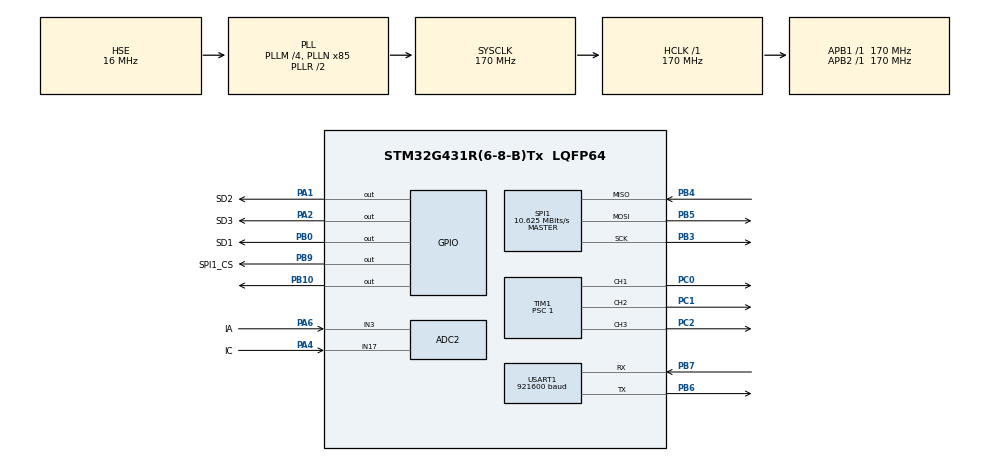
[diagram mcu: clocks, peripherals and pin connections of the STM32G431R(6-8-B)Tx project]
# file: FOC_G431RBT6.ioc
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ADC2.ContinuousConvMode=DISABLE
ADC2.EOCSelection=ADC_EOC_SINGLE_CONV
ADC2.EnableInjectedConversion=ENABLE
ADC2.EnableRegularConversion=DISABLE
ADC2.ExternalTrigInjecConv=ADC_EXTERNALTRIGINJEC_T1_TRGO
ADC2.InjNumberOfConversion=2
ADC2.InjectedChannel-1\#ChannelInjectedConversion=ADC_CHANNEL_3
ADC2.InjectedChannel-3\#ChannelInjectedConversion=ADC_CHANNEL_17
ADC2.InjectedOffsetNumber-1\#ChannelInjectedConversion=ADC_OFFSET_NONE
ADC2.InjectedOffsetNumber-3\#ChannelInjectedConversion=ADC_OFFSET_NONE
ADC2.InjectedRank-1\#ChannelInjectedConversion=1
ADC2.InjectedRank-3\#ChannelInjectedConversion=2
ADC2.InjectedSamplingTime-1\#ChannelInjectedConversion=ADC_SAMPLETIME_24CYCLES_5
ADC2.InjectedSamplingTime-3\#ChannelInjectedConversion=ADC_SAMPLETIME_24CYCLES_5
ADC2.injectedQueueMode=DISABLE
Dma.Request0=USART1_RX
Dma.Request1=USART1_TX
Dma.Request2=SPI1_RX
Dma.Request3=SPI1_TX
Dma.SPI1_RX.2.Direction=DMA_PERIPH_TO_MEMORY
Dma.SPI1_RX.2.EventEnable=DISABLE
Dma.SPI1_RX.2.Instance=DMA1_Channel3
Dma.SPI1_RX.2.MemDataAlignment=DMA_MDATAALIGN_BYTE
Dma.SPI1_RX.2.MemInc=DMA_MINC_ENABLE
Dma.SPI1_RX.2.Mode=DMA_NORMAL
Dma.SPI1_RX.2.PeriphDataAlignment=DMA_PDATAALIGN_BYTE
Dma.SPI1_RX.2.PeriphInc=DMA_PINC_DISABLE
Dma.SPI1_RX.2.Polarity=HAL_DMAMUX_REQ_GEN_RISING
Dma.SPI1_RX.2.Priority=DMA_PRIORITY_LOW
Dma.SPI1_RX.2.RequestNumber=1
Dma.SPI1_RX.2.SignalID=NONE
Dma.SPI1_RX.2.SyncEnable=DISABLE
Dma.SPI1_RX.2.SyncPolarity=HAL_DMAMUX_SYNC_NO_EVENT
Dma.SPI1_RX.2.SyncRequestNumber=1
Dma.SPI1_RX.2.SyncSignalID=NONE
Dma.SPI1_TX.3.Direction=DMA_MEMORY_TO_PERIPH
Dma.SPI1_TX.3.EventEnable=DISABLE
Dma.SPI1_TX.3.Instance=DMA1_Channel4
Dma.SPI1_TX.3.MemDataAlignment=DMA_MDATAALIGN_BYTE
Dma.SPI1_TX.3.MemInc=DMA_MINC_ENABLE
Dma.SPI1_TX.3.Mode=DMA_NORMAL
Dma.SPI1_TX.3.PeriphDataAlignment=DMA_PDATAALIGN_BYTE
Dma.SPI1_TX.3.PeriphInc=DMA_PINC_DISABLE
Dma.SPI1_TX.3.Polarity=HAL_DMAMUX_REQ_GEN_RISING
Dma.SPI1_TX.3.Priority=DMA_PRIORITY_LOW
Dma.SPI1_TX.3.RequestNumber=1
Dma.SPI1_TX.3.SignalID=NONE
Dma.SPI1_TX.3.SyncEnable=DISABLE
Dma.SPI1_TX.3.SyncPolarity=HAL_DMAMUX_SYNC_NO_EVENT
Dma.SPI1_TX.3.SyncRequestNumber=1
Dma.SPI1_TX.3.SyncSignalID=NONE
Dma.USART1_RX.0.Direction=DMA_PERIPH_TO_MEMORY
Dma.USART1_RX.0.EventEnable=DISABLE
Dma.USART1_RX.0.Instance=DMA1_Channel1
Dma.USART1_RX.0.MemDataAlignment=DMA_MDATAALIGN_BYTE
Dma.USART1_RX.0.MemInc=DMA_MINC_ENABLE
Dma.USART1_RX.0.Mode=DMA_NORMAL
Dma.USART1_RX.0.PeriphDataAlignment=DMA_PDATAALIGN_BYTE
Dma.USART1_RX.0.PeriphInc=DMA_PINC_DISABLE
Dma.USART1_RX.0.Polarity=HAL_DMAMUX_REQ_GEN_RISING
Dma.USART1_RX.0.Priority=DMA_PRIORITY_LOW
Dma.USART1_RX.0.RequestNumber=1
Dma.USART1_RX.0.SignalID=NONE
Dma.USART1_RX.0.SyncEnable=DISABLE
Dma.USART1_RX.0.SyncPolarity=HAL_DMAMUX_SYNC_NO_EVENT
Dma.USART1_RX.0.SyncRequestNumber=1
Dma.USART1_RX.0.SyncSignalID=NONE
Dma.USART1_TX.1.Direction=DMA_MEMORY_TO_PERIPH
Dma.USART1_TX.1.EventEnable=DISABLE
Dma.USART1_TX.1.Instance=DMA1_Channel2
Dma.USART1_TX.1.MemDataAlignment=DMA_MDATAALIGN_BYTE
Dma.USART1_TX.1.MemInc=DMA_MINC_ENABLE
Dma.USART1_TX.1.Mode=DMA_NORMAL
Dma.USART1_TX.1.PeriphDataAlignment=DMA_PDATAALIGN_BYTE
Dma.USART1_TX.1.PeriphInc=DMA_PINC_DISABLE
Dma.USART1_TX.1.Polarity=HAL_DMAMUX_REQ_GEN_RISING
Dma.USART1_TX.1.Priority=DMA_PRIORITY_MEDIUM
Dma.USART1_TX.1.RequestNumber=1
Dma.USART1_TX.1.SignalID=NONE
Dma.USART1_TX.1.SyncEnable=DISABLE
Dma.USART1_TX.1.SyncPolarity=HAL_DMAMUX_SYNC_NO_EVENT
Dma.USART1_TX.1.SyncRequestNumber=1
Dma.USART1_TX.1.SyncSignalID=NONE
Mcu.Family=STM32G4
Mcu.Name=STM32G431R(6-8-B)Tx
Mcu.Package=LQFP64
Mcu.UserConstants=motor_pwm_freq,24000
NVIC.ADC1_2_IRQn=true\:0\:0\:true\:false\:true\:true\:true\:true
NVIC.DMA1_Channel1_IRQn=true\:0\:0\:false\:false\:true\:false\:true\:true
NVIC.DMA1_Channel2_IRQn=true\:0\:0\:false\:false\:true\:false\:true\:true
NVIC.DMA1_Channel3_IRQn=true\:0\:0\:false\:false\:true\:false\:true\:true
NVIC.DMA1_Channel4_IRQn=true\:0\:0\:false\:false\:true\:false\:true\:true
NVIC.PriorityGroup=NVIC_PRIORITYGROUP_4
PA1.GPIO_Label=SD2
PA1.GPIO_Speed=GPIO_SPEED_FREQ_VERY_HIGH
PA1.PinState=GPIO_PIN_RESET
PA1.Signal=GPIO_Output
PA13.Mode=Serial_Wire
PA13.Signal=SYS_JTMS-SWDIO
PA14.Mode=Serial_Wire
PA14.Signal=SYS_JTCK-SWCLK
PA2.GPIO_Label=SD3
PA2.GPIO_Speed=GPIO_SPEED_FREQ_VERY_HIGH
PA2.PinState=GPIO_PIN_RESET
PA2.Signal=GPIO_Output
PA4.GPIO_Label=IC
PA4.Mode=IN17-Single-Ended
PA4.Signal=ADC2_IN17
PA6.GPIO_Label=IA
PA6.Mode=IN3-Single-Ended
PA6.Signal=ADC2_IN3
PB0.GPIO_Label=SD1
PB0.GPIO_Speed=GPIO_SPEED_FREQ_VERY_HIGH
PB0.PinState=GPIO_PIN_RESET
PB0.Signal=GPIO_Output
PB10.GPIO_Speed=GPIO_SPEED_FREQ_HIGH
PB10.PinState=GPIO_PIN_RESET
PB10.Signal=GPIO_Output
PB3.Mode=Full_Duplex_Master
PB3.Signal=SPI1_SCK
PB4.Mode=Full_Duplex_Master
PB4.Signal=SPI1_MISO
PB5.Mode=Full_Duplex_Master
PB5.Signal=SPI1_MOSI
PB6.Mode=Asynchronous
PB6.Signal=USART1_TX
PB7.Mode=Asynchronous
PB7.Signal=USART1_RX
PB9.GPIO_Label=SPI1_CS
PB9.PinState=GPIO_PIN_SET
PB9.Signal=GPIO_Output
PC0.Signal=S_TIM1_CH1
PC1.Signal=S_TIM1_CH2
PC2.Signal=S_TIM1_CH3
PF0-OSC_IN.Mode=HSE-External-Oscillator
PF0-OSC_IN.Signal=RCC_OSC_IN
PF1-OSC_OUT.Mode=HSE-External-Oscillator
PF1-OSC_OUT.Signal=RCC_OSC_OUT
ProjectManager.HeapSize=0x400
ProjectManager.StackSize=0x600
ProjectManager.TargetToolchain=MDK-ARM V5
RCC.ADC12Freq_Value=170000000
RCC.AHBFreq_Value=170000000
RCC.APB1Freq_Value=170000000
RCC.APB1TimFreq_Value=170000000
RCC.APB2Freq_Value=170000000
RCC.APB2TimFreq_Value=170000000
RCC.CortexFreq_Value=170000000
RCC.EXTERNAL_CLOCK_VALUE=12288000
RCC.HCLKFreq_Value=170000000
RCC.HSE_VALUE=16000000
RCC.HSI48_VALUE=48000000
RCC.HSI_VALUE=16000000
RCC.LSE_VALUE=32768
RCC.PLLM=RCC_PLLM_DIV4
RCC.PLLN=85
RCC.PLLSourceVirtual=RCC_PLLSOURCE_HSE
RCC.SYSCLKFreq_VALUE=170000000
RCC.SYSCLKSource=RCC_SYSCLKSOURCE_PLLCLK
RCC.USBFreq_Value=170000000
RCC.VCOOutputFreq_Value=340000000
SH.S_TIM1_CH1.0=TIM1_CH1,PWM Generation1 CH1
SH.S_TIM1_CH2.0=TIM1_CH2,PWM Generation2 CH2
SH.S_TIM1_CH3.0=TIM1_CH3,PWM Generation3 CH3
SPI1.BaudRatePrescaler=SPI_BAUDRATEPRESCALER_16
SPI1.CLKPhase=SPI_PHASE_2EDGE
SPI1.CLKPolarity=SPI_POLARITY_HIGH
SPI1.CalculateBaudRate=10.625 MBits/s
SPI1.DataSize=SPI_DATASIZE_8BIT
SPI1.Direction=SPI_DIRECTION_2LINES
SPI1.Mode=SPI_MODE_MASTER
SPI1.VirtualType=VM_MASTER
STMicroelectronics.X-CUBE-ALGOBUILD.1.4.0.LibraryCcDSPOoLibraryJjDSPOoLibrary=true
TIM1.AutoReloadPreload=TIM_AUTORELOAD_PRELOAD_ENABLE
TIM1.AutomaticOutput=TIM_AUTOMATICOUTPUT_DISABLE
TIM1.Break2Polarity=TIM_BREAK2POLARITY_LOW
TIM1.Break2State=TIM_BREAK2_DISABLE
TIM1.BreakPolarity=TIM_BREAKPOLARITY_LOW
TIM1.BreakState=TIM_BREAK_DISABLE
TIM1.Channel-PWM\ Generation1\ CH1=TIM_CHANNEL_1
TIM1.Channel-PWM\ Generation2\ CH2=TIM_CHANNEL_2
TIM1.Channel-PWM\ Generation3\ CH3=TIM_CHANNEL_3
TIM1.CounterMode=TIM_COUNTERMODE_CENTERALIGNED3
TIM1.LockLevel=TIM_LOCKLEVEL_1
TIM1.OCMode_PWM-PWM\ Generation1\ CH1=TIM_OCMODE_PWM2
TIM1.OCMode_PWM-PWM\ Generation2\ CH2=TIM_OCMODE_PWM2
TIM1.OCMode_PWM-PWM\ Generation3\ CH3=TIM_OCMODE_PWM2
TIM1.PeriodNoDither=(85000000/motor_pwm_freq)
TIM1.Prescaler=1
TIM1.RepetitionCounter=1
TIM1.TIM_MasterOutputTrigger=TIM_TRGO_UPDATE
USART1.BaudRate=921600
USART1.VirtualMode-Asynchronous=VM_ASYNC
VP_STMicroelectronics.X-CUBE-ALGOBUILD_VS_DSPOoLibraryJjLibrary_1.4.0_1.4.0.Mode=DSPOoLibraryJjLibrary
VP_SYS_VS_DBSignals.Mode=DisableDeadBatterySignals
VP_TIM1_VS_ClockSourceINT.Mode=Internal
board=custom

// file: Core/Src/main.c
/* USER CODE BEGIN Header */
/**
  ******************************************************************************
  * @file           : main.c
  * @brief          : Main program body
  ******************************************************************************
  * @attention
  *
  * Copyright (c) 2025 STMicroelectronics.
  * All rights reserved.
  *
  * This software is licensed under terms that can be found in the LICENSE file
  * in the root directory of this software component.
  * If no LICENSE file comes with this software, it is provided AS-IS.
  *
  ******************************************************************************
  */
/* USER CODE END Header */
#include "main.h"
#include "adc.h"
#include "dma.h"
#include "spi.h"
#include "tim.h"
#include "usart.h"
#include "gpio.h"

/* USER CODE BEGIN Includes */
#include <math.h>
/* USER CODE END Includes */

void SystemClock_Config(void);

int main(void)
{

  /* MCU Configuration--------------------------------------------------------*/

  /* Reset of all peripherals, Initializes the Flash interface and the Systick. */
  HAL_Init();

  /* Configure the system clock */
  SystemClock_Config();

  /* Initialize all configured peripherals */
  MX_GPIO_Init();
  MX_DMA_Init();
  MX_SPI1_Init();
  MX_USART1_UART_Init();
  MX_TIM1_Init();
  MX_ADC2_Init();
  /* USER CODE BEGIN 2 */
  uint8_t i=0;
  float temp;
  /* USER CODE END 2 */

  /* Infinite loop */
  while (1)
  {
//	HAL_UART_Transmit_DMA(&huart1, buf, sizeof(buf));
//	while (huart1.gState != HAL_UART_STATE_READY);
	temp=sinf(i*3.1415926/180);
	i++;
	HAL_UART_Transmit(&huart1, (uint8_t *)&i, sizeof(i), HAL_MAX_DELAY);
	HAL_Delay(1);
  }
}

void SystemClock_Config(void)
{
  RCC_OscInitTypeDef RCC_OscInitStruct = {0};
  RCC_ClkInitTypeDef RCC_ClkInitStruct = {0};

  /** Configure the main internal regulator output voltage
  */
  HAL_PWREx_ControlVoltageScaling(PWR_REGULATOR_VOLTAGE_SCALE1_BOOST);

  /** Initializes the RCC Oscillators according to the specified parameters
  * in the RCC_OscInitTypeDef structure.
  */
  RCC_OscInitStruct.OscillatorType = RCC_OSCILLATORTYPE_HSE;
  RCC_OscInitStruct.HSEState = RCC_HSE_ON;
  RCC_OscInitStruct.PLL.PLLState = RCC_PLL_ON;
  RCC_OscInitStruct.PLL.PLLSource = RCC_PLLSOURCE_HSE;
  RCC_OscInitStruct.PLL.PLLM = RCC_PLLM_DIV4;
  RCC_OscInitStruct.PLL.PLLN = 85;
  RCC_OscInitStruct.PLL.PLLP = RCC_PLLP_DIV2;
  RCC_OscInitStruct.PLL.PLLQ = RCC_PLLQ_DIV2;
  RCC_OscInitStruct.PLL.PLLR = RCC_PLLR_DIV2;
  if (HAL_RCC_OscConfig(&RCC_OscInitStruct) != HAL_OK)
  {
    Error_Handler();
  }

  /** Initializes the CPU, AHB and APB buses clocks
  */
  RCC_ClkInitStruct.ClockType = RCC_CLOCKTYPE_HCLK|RCC_CLOCKTYPE_SYSCLK
                              |RCC_CLOCKTYPE_PCLK1|RCC_CLOCKTYPE_PCLK2;
  RCC_ClkInitStruct.SYSCLKSource = RCC_SYSCLKSOURCE_PLLCLK;
  RCC_ClkInitStruct.AHBCLKDivider = RCC_SYSCLK_DIV1;
  RCC_ClkInitStruct.APB1CLKDivider = RCC_HCLK_DIV1;
  RCC_ClkInitStruct.APB2CLKDivider = RCC_HCLK_DIV1;

  if (HAL_RCC_ClockConfig(&RCC_ClkInitStruct, FLASH_LATENCY_4) != HAL_OK)
  {
    Error_Handler();
  }
}

void Error_Handler(void)
{
  __disable_irq();
  while (1)
  {
  }
}
